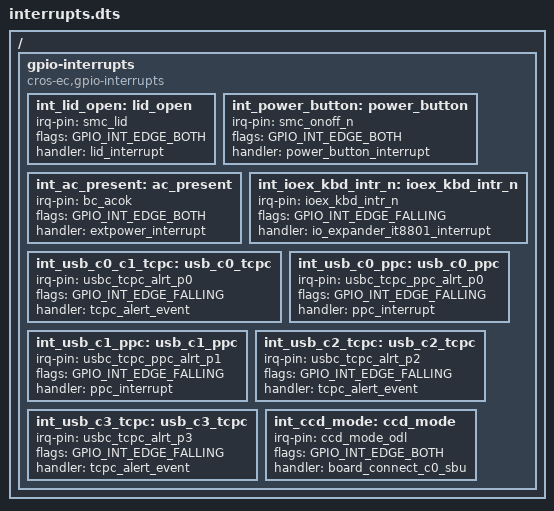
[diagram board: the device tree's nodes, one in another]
/* Copyright 2022 The Chromium OS Authors. All rights reserved.
 * Use of this source code is governed by a BSD-style license that can be
 * found in the LICENSE file.
 */
/ {
	gpio-interrupts {
		compatible = "cros-ec,gpio-interrupts";

		int_lid_open: lid_open {
			irq-pin = <&smc_lid>;
			flags = <GPIO_INT_EDGE_BOTH>;
			handler = "lid_interrupt";
		};
		int_power_button: power_button {
			irq-pin = <&smc_onoff_n>;
			flags = <GPIO_INT_EDGE_BOTH>;
			handler = "power_button_interrupt";
		};
		int_ac_present: ac_present {
			irq-pin = <&bc_acok>;
			flags = <GPIO_INT_EDGE_BOTH>;
			handler = "extpower_interrupt";
		};
		int_ioex_kbd_intr_n: ioex_kbd_intr_n {
			irq-pin = <&ioex_kbd_intr_n>;
			flags = <GPIO_INT_EDGE_FALLING>;
			handler = "io_expander_it8801_interrupt";
		};
		int_usb_c0_c1_tcpc: usb_c0_tcpc {
			irq-pin = <&usbc_tcpc_alrt_p0>;
			flags = <GPIO_INT_EDGE_FALLING>;
			handler = "tcpc_alert_event";
		};
		int_usb_c0_ppc: usb_c0_ppc {
			irq-pin = <&usbc_tcpc_ppc_alrt_p0>;
			flags = <GPIO_INT_EDGE_FALLING>;
			handler = "ppc_interrupt";
		};
		int_usb_c1_ppc: usb_c1_ppc {
			irq-pin = <&usbc_tcpc_ppc_alrt_p1>;
			flags = <GPIO_INT_EDGE_FALLING>;
			handler = "ppc_interrupt";
		};
		int_usb_c2_tcpc: usb_c2_tcpc {
			irq-pin = <&usbc_tcpc_alrt_p2>;
			flags = <GPIO_INT_EDGE_FALLING>;
			handler = "tcpc_alert_event";
		};
		int_usb_c3_tcpc: usb_c3_tcpc {
			irq-pin = <&usbc_tcpc_alrt_p3>;
			flags = <GPIO_INT_EDGE_FALLING>;
			handler = "tcpc_alert_event";
		};
		int_ccd_mode: ccd_mode {
			irq-pin = <&ccd_mode_odl>;
			flags = <GPIO_INT_EDGE_BOTH>;
			handler = "board_connect_c0_sbu";
		};
	};
};
